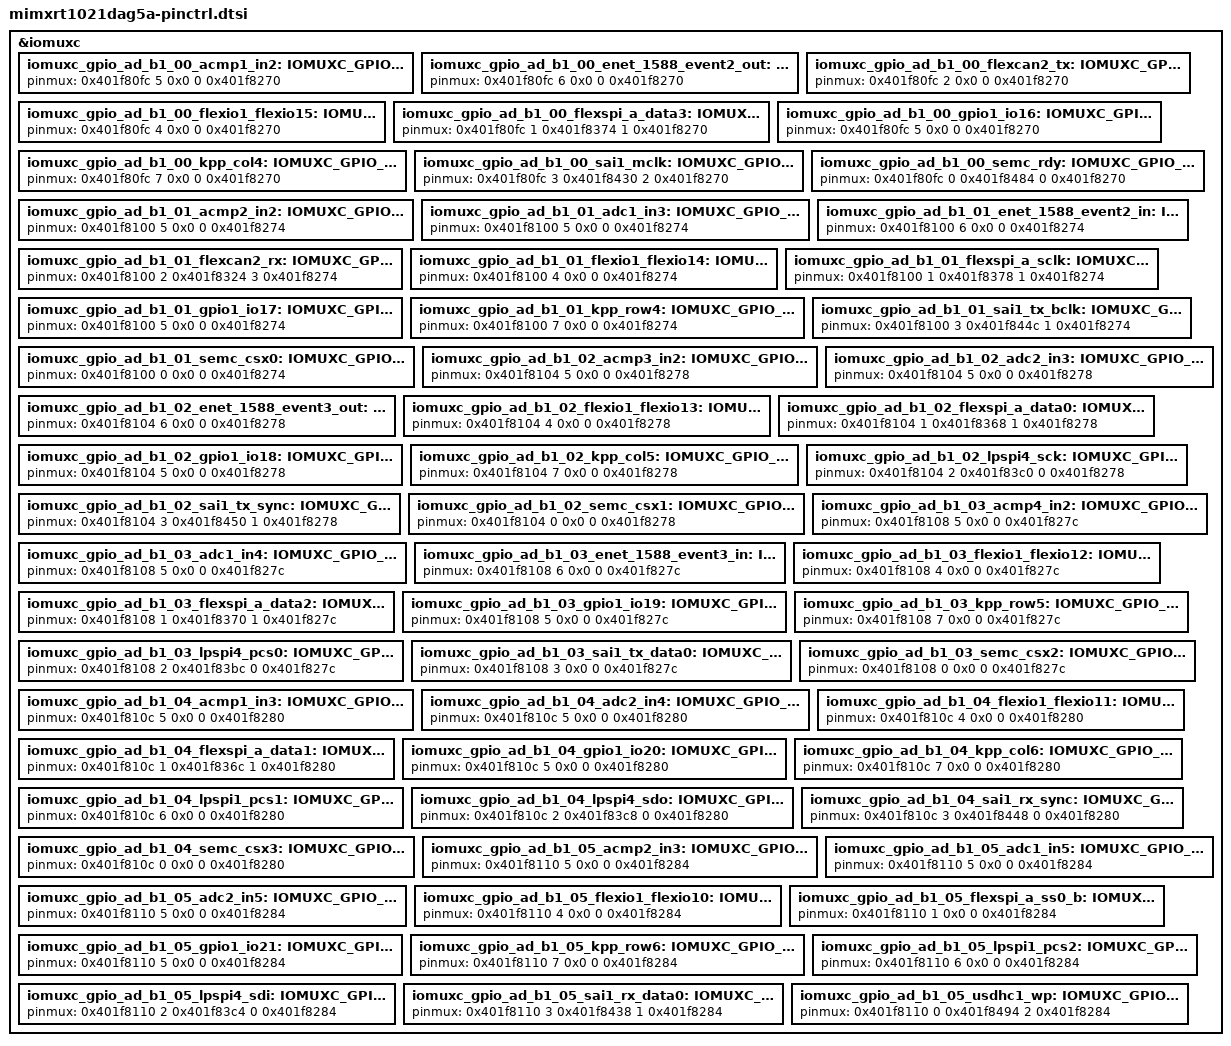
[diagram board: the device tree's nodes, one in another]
/*
 * Copyright (c) 2022, NXP
 * SPDX-License-Identifier: Apache-2.0
 *
 * Note: File generated by rt_cfg_utils.py
 * from configuration data for MIMXRT1021DAG5A
 */

/*
 * Delta-deduplicated by dedup_pinctrl.py:
 * based on mimxrt1024dag5a-pinctrl.dtsi with this part's differences applied
 * below (0 removed, 0 changed,
 * 60 added). Regenerate with dedup_pinctrl.py;
 * do not edit by hand.
 * target-hash: 459db1daa55398a1
 */

#include "mimxrt1024dag5a-pinctrl.dtsi"

&iomuxc {
	/omit-if-no-ref/ iomuxc_gpio_ad_b1_00_acmp1_in2: IOMUXC_GPIO_AD_B1_00_ACMP1_IN2 {
		pinmux = <0x401f80fc 5 0x0 0 0x401f8270>;
	};
	/omit-if-no-ref/ iomuxc_gpio_ad_b1_00_enet_1588_event2_out: IOMUXC_GPIO_AD_B1_00_ENET_1588_EVENT2_OUT {
		pinmux = <0x401f80fc 6 0x0 0 0x401f8270>;
	};
	/omit-if-no-ref/ iomuxc_gpio_ad_b1_00_flexcan2_tx: IOMUXC_GPIO_AD_B1_00_FLEXCAN2_TX {
		pinmux = <0x401f80fc 2 0x0 0 0x401f8270>;
	};
	/omit-if-no-ref/ iomuxc_gpio_ad_b1_00_flexio1_flexio15: IOMUXC_GPIO_AD_B1_00_FLEXIO1_FLEXIO15 {
		pinmux = <0x401f80fc 4 0x0 0 0x401f8270>;
	};
	/omit-if-no-ref/ iomuxc_gpio_ad_b1_00_flexspi_a_data3: IOMUXC_GPIO_AD_B1_00_FLEXSPI_A_DATA3 {
		pinmux = <0x401f80fc 1 0x401f8374 1 0x401f8270>;
	};
	/omit-if-no-ref/ iomuxc_gpio_ad_b1_00_gpio1_io16: IOMUXC_GPIO_AD_B1_00_GPIO1_IO16 {
		pinmux = <0x401f80fc 5 0x0 0 0x401f8270>;
	};
	/omit-if-no-ref/ iomuxc_gpio_ad_b1_00_kpp_col4: IOMUXC_GPIO_AD_B1_00_KPP_COL4 {
		pinmux = <0x401f80fc 7 0x0 0 0x401f8270>;
	};
	/omit-if-no-ref/ iomuxc_gpio_ad_b1_00_sai1_mclk: IOMUXC_GPIO_AD_B1_00_SAI1_MCLK {
		pinmux = <0x401f80fc 3 0x401f8430 2 0x401f8270>;
	};
	/omit-if-no-ref/ iomuxc_gpio_ad_b1_00_semc_rdy: IOMUXC_GPIO_AD_B1_00_SEMC_RDY {
		pinmux = <0x401f80fc 0 0x401f8484 0 0x401f8270>;
	};
	/omit-if-no-ref/ iomuxc_gpio_ad_b1_01_acmp2_in2: IOMUXC_GPIO_AD_B1_01_ACMP2_IN2 {
		pinmux = <0x401f8100 5 0x0 0 0x401f8274>;
	};
	/omit-if-no-ref/ iomuxc_gpio_ad_b1_01_adc1_in3: IOMUXC_GPIO_AD_B1_01_ADC1_IN3 {
		pinmux = <0x401f8100 5 0x0 0 0x401f8274>;
	};
	/omit-if-no-ref/ iomuxc_gpio_ad_b1_01_enet_1588_event2_in: IOMUXC_GPIO_AD_B1_01_ENET_1588_EVENT2_IN {
		pinmux = <0x401f8100 6 0x0 0 0x401f8274>;
	};
	/omit-if-no-ref/ iomuxc_gpio_ad_b1_01_flexcan2_rx: IOMUXC_GPIO_AD_B1_01_FLEXCAN2_RX {
		pinmux = <0x401f8100 2 0x401f8324 3 0x401f8274>;
	};
	/omit-if-no-ref/ iomuxc_gpio_ad_b1_01_flexio1_flexio14: IOMUXC_GPIO_AD_B1_01_FLEXIO1_FLEXIO14 {
		pinmux = <0x401f8100 4 0x0 0 0x401f8274>;
	};
	/omit-if-no-ref/ iomuxc_gpio_ad_b1_01_flexspi_a_sclk: IOMUXC_GPIO_AD_B1_01_FLEXSPI_A_SCLK {
		pinmux = <0x401f8100 1 0x401f8378 1 0x401f8274>;
	};
	/omit-if-no-ref/ iomuxc_gpio_ad_b1_01_gpio1_io17: IOMUXC_GPIO_AD_B1_01_GPIO1_IO17 {
		pinmux = <0x401f8100 5 0x0 0 0x401f8274>;
	};
	/omit-if-no-ref/ iomuxc_gpio_ad_b1_01_kpp_row4: IOMUXC_GPIO_AD_B1_01_KPP_ROW4 {
		pinmux = <0x401f8100 7 0x0 0 0x401f8274>;
	};
	/omit-if-no-ref/ iomuxc_gpio_ad_b1_01_sai1_tx_bclk: IOMUXC_GPIO_AD_B1_01_SAI1_TX_BCLK {
		pinmux = <0x401f8100 3 0x401f844c 1 0x401f8274>;
	};
	/omit-if-no-ref/ iomuxc_gpio_ad_b1_01_semc_csx0: IOMUXC_GPIO_AD_B1_01_SEMC_CSX0 {
		pinmux = <0x401f8100 0 0x0 0 0x401f8274>;
	};
	/omit-if-no-ref/ iomuxc_gpio_ad_b1_02_acmp3_in2: IOMUXC_GPIO_AD_B1_02_ACMP3_IN2 {
		pinmux = <0x401f8104 5 0x0 0 0x401f8278>;
	};
	/omit-if-no-ref/ iomuxc_gpio_ad_b1_02_adc2_in3: IOMUXC_GPIO_AD_B1_02_ADC2_IN3 {
		pinmux = <0x401f8104 5 0x0 0 0x401f8278>;
	};
	/omit-if-no-ref/ iomuxc_gpio_ad_b1_02_enet_1588_event3_out: IOMUXC_GPIO_AD_B1_02_ENET_1588_EVENT3_OUT {
		pinmux = <0x401f8104 6 0x0 0 0x401f8278>;
	};
	/omit-if-no-ref/ iomuxc_gpio_ad_b1_02_flexio1_flexio13: IOMUXC_GPIO_AD_B1_02_FLEXIO1_FLEXIO13 {
		pinmux = <0x401f8104 4 0x0 0 0x401f8278>;
	};
	/omit-if-no-ref/ iomuxc_gpio_ad_b1_02_flexspi_a_data0: IOMUXC_GPIO_AD_B1_02_FLEXSPI_A_DATA0 {
		pinmux = <0x401f8104 1 0x401f8368 1 0x401f8278>;
	};
	/omit-if-no-ref/ iomuxc_gpio_ad_b1_02_gpio1_io18: IOMUXC_GPIO_AD_B1_02_GPIO1_IO18 {
		pinmux = <0x401f8104 5 0x0 0 0x401f8278>;
	};
	/omit-if-no-ref/ iomuxc_gpio_ad_b1_02_kpp_col5: IOMUXC_GPIO_AD_B1_02_KPP_COL5 {
		pinmux = <0x401f8104 7 0x0 0 0x401f8278>;
	};
	/omit-if-no-ref/ iomuxc_gpio_ad_b1_02_lpspi4_sck: IOMUXC_GPIO_AD_B1_02_LPSPI4_SCK {
		pinmux = <0x401f8104 2 0x401f83c0 0 0x401f8278>;
	};
	/omit-if-no-ref/ iomuxc_gpio_ad_b1_02_sai1_tx_sync: IOMUXC_GPIO_AD_B1_02_SAI1_TX_SYNC {
		pinmux = <0x401f8104 3 0x401f8450 1 0x401f8278>;
	};
	/omit-if-no-ref/ iomuxc_gpio_ad_b1_02_semc_csx1: IOMUXC_GPIO_AD_B1_02_SEMC_CSX1 {
		pinmux = <0x401f8104 0 0x0 0 0x401f8278>;
	};
	/omit-if-no-ref/ iomuxc_gpio_ad_b1_03_acmp4_in2: IOMUXC_GPIO_AD_B1_03_ACMP4_IN2 {
		pinmux = <0x401f8108 5 0x0 0 0x401f827c>;
	};
	/omit-if-no-ref/ iomuxc_gpio_ad_b1_03_adc1_in4: IOMUXC_GPIO_AD_B1_03_ADC1_IN4 {
		pinmux = <0x401f8108 5 0x0 0 0x401f827c>;
	};
	/omit-if-no-ref/ iomuxc_gpio_ad_b1_03_enet_1588_event3_in: IOMUXC_GPIO_AD_B1_03_ENET_1588_EVENT3_IN {
		pinmux = <0x401f8108 6 0x0 0 0x401f827c>;
	};
	/omit-if-no-ref/ iomuxc_gpio_ad_b1_03_flexio1_flexio12: IOMUXC_GPIO_AD_B1_03_FLEXIO1_FLEXIO12 {
		pinmux = <0x401f8108 4 0x0 0 0x401f827c>;
	};
	/omit-if-no-ref/ iomuxc_gpio_ad_b1_03_flexspi_a_data2: IOMUXC_GPIO_AD_B1_03_FLEXSPI_A_DATA2 {
		pinmux = <0x401f8108 1 0x401f8370 1 0x401f827c>;
	};
	/omit-if-no-ref/ iomuxc_gpio_ad_b1_03_gpio1_io19: IOMUXC_GPIO_AD_B1_03_GPIO1_IO19 {
		pinmux = <0x401f8108 5 0x0 0 0x401f827c>;
	};
	/omit-if-no-ref/ iomuxc_gpio_ad_b1_03_kpp_row5: IOMUXC_GPIO_AD_B1_03_KPP_ROW5 {
		pinmux = <0x401f8108 7 0x0 0 0x401f827c>;
	};
	/omit-if-no-ref/ iomuxc_gpio_ad_b1_03_lpspi4_pcs0: IOMUXC_GPIO_AD_B1_03_LPSPI4_PCS0 {
		pinmux = <0x401f8108 2 0x401f83bc 0 0x401f827c>;
	};
	/omit-if-no-ref/ iomuxc_gpio_ad_b1_03_sai1_tx_data0: IOMUXC_GPIO_AD_B1_03_SAI1_TX_DATA0 {
		pinmux = <0x401f8108 3 0x0 0 0x401f827c>;
	};
	/omit-if-no-ref/ iomuxc_gpio_ad_b1_03_semc_csx2: IOMUXC_GPIO_AD_B1_03_SEMC_CSX2 {
		pinmux = <0x401f8108 0 0x0 0 0x401f827c>;
	};
	/omit-if-no-ref/ iomuxc_gpio_ad_b1_04_acmp1_in3: IOMUXC_GPIO_AD_B1_04_ACMP1_IN3 {
		pinmux = <0x401f810c 5 0x0 0 0x401f8280>;
	};
	/omit-if-no-ref/ iomuxc_gpio_ad_b1_04_adc2_in4: IOMUXC_GPIO_AD_B1_04_ADC2_IN4 {
		pinmux = <0x401f810c 5 0x0 0 0x401f8280>;
	};
	/omit-if-no-ref/ iomuxc_gpio_ad_b1_04_flexio1_flexio11: IOMUXC_GPIO_AD_B1_04_FLEXIO1_FLEXIO11 {
		pinmux = <0x401f810c 4 0x0 0 0x401f8280>;
	};
	/omit-if-no-ref/ iomuxc_gpio_ad_b1_04_flexspi_a_data1: IOMUXC_GPIO_AD_B1_04_FLEXSPI_A_DATA1 {
		pinmux = <0x401f810c 1 0x401f836c 1 0x401f8280>;
	};
	/omit-if-no-ref/ iomuxc_gpio_ad_b1_04_gpio1_io20: IOMUXC_GPIO_AD_B1_04_GPIO1_IO20 {
		pinmux = <0x401f810c 5 0x0 0 0x401f8280>;
	};
	/omit-if-no-ref/ iomuxc_gpio_ad_b1_04_kpp_col6: IOMUXC_GPIO_AD_B1_04_KPP_COL6 {
		pinmux = <0x401f810c 7 0x0 0 0x401f8280>;
	};
	/omit-if-no-ref/ iomuxc_gpio_ad_b1_04_lpspi1_pcs1: IOMUXC_GPIO_AD_B1_04_LPSPI1_PCS1 {
		pinmux = <0x401f810c 6 0x0 0 0x401f8280>;
	};
	/omit-if-no-ref/ iomuxc_gpio_ad_b1_04_lpspi4_sdo: IOMUXC_GPIO_AD_B1_04_LPSPI4_SDO {
		pinmux = <0x401f810c 2 0x401f83c8 0 0x401f8280>;
	};
	/omit-if-no-ref/ iomuxc_gpio_ad_b1_04_sai1_rx_sync: IOMUXC_GPIO_AD_B1_04_SAI1_RX_SYNC {
		pinmux = <0x401f810c 3 0x401f8448 0 0x401f8280>;
	};
	/omit-if-no-ref/ iomuxc_gpio_ad_b1_04_semc_csx3: IOMUXC_GPIO_AD_B1_04_SEMC_CSX3 {
		pinmux = <0x401f810c 0 0x0 0 0x401f8280>;
	};
	/omit-if-no-ref/ iomuxc_gpio_ad_b1_05_acmp2_in3: IOMUXC_GPIO_AD_B1_05_ACMP2_IN3 {
		pinmux = <0x401f8110 5 0x0 0 0x401f8284>;
	};
	/omit-if-no-ref/ iomuxc_gpio_ad_b1_05_adc1_in5: IOMUXC_GPIO_AD_B1_05_ADC1_IN5 {
		pinmux = <0x401f8110 5 0x0 0 0x401f8284>;
	};
	/omit-if-no-ref/ iomuxc_gpio_ad_b1_05_adc2_in5: IOMUXC_GPIO_AD_B1_05_ADC2_IN5 {
		pinmux = <0x401f8110 5 0x0 0 0x401f8284>;
	};
	/omit-if-no-ref/ iomuxc_gpio_ad_b1_05_flexio1_flexio10: IOMUXC_GPIO_AD_B1_05_FLEXIO1_FLEXIO10 {
		pinmux = <0x401f8110 4 0x0 0 0x401f8284>;
	};
	/omit-if-no-ref/ iomuxc_gpio_ad_b1_05_flexspi_a_ss0_b: IOMUXC_GPIO_AD_B1_05_FLEXSPI_A_SS0_B {
		pinmux = <0x401f8110 1 0x0 0 0x401f8284>;
	};
	/omit-if-no-ref/ iomuxc_gpio_ad_b1_05_gpio1_io21: IOMUXC_GPIO_AD_B1_05_GPIO1_IO21 {
		pinmux = <0x401f8110 5 0x0 0 0x401f8284>;
	};
	/omit-if-no-ref/ iomuxc_gpio_ad_b1_05_kpp_row6: IOMUXC_GPIO_AD_B1_05_KPP_ROW6 {
		pinmux = <0x401f8110 7 0x0 0 0x401f8284>;
	};
	/omit-if-no-ref/ iomuxc_gpio_ad_b1_05_lpspi1_pcs2: IOMUXC_GPIO_AD_B1_05_LPSPI1_PCS2 {
		pinmux = <0x401f8110 6 0x0 0 0x401f8284>;
	};
	/omit-if-no-ref/ iomuxc_gpio_ad_b1_05_lpspi4_sdi: IOMUXC_GPIO_AD_B1_05_LPSPI4_SDI {
		pinmux = <0x401f8110 2 0x401f83c4 0 0x401f8284>;
	};
	/omit-if-no-ref/ iomuxc_gpio_ad_b1_05_sai1_rx_data0: IOMUXC_GPIO_AD_B1_05_SAI1_RX_DATA0 {
		pinmux = <0x401f8110 3 0x401f8438 1 0x401f8284>;
	};
	/omit-if-no-ref/ iomuxc_gpio_ad_b1_05_usdhc1_wp: IOMUXC_GPIO_AD_B1_05_USDHC1_WP {
		pinmux = <0x401f8110 0 0x401f8494 2 0x401f8284>;
	};
};
